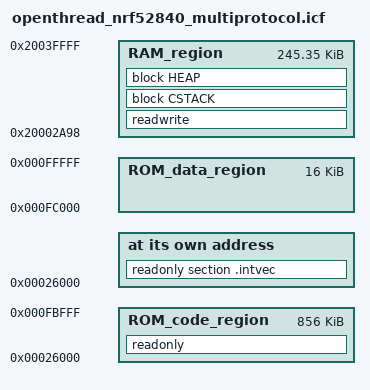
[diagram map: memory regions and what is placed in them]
/*###ICF### Section handled by ICF editor, don't touch! ****/
/*-Editor annotation file-*/
/* IcfEditorFile="$TOOLKIT_DIR$\config\ide\IcfEditor\cortex_v1_0.xml" */
/*-Specials-*/
define symbol __ICFEDIT_intvec_start__ = 0x26000;
/*-Memory Regions-*/
define symbol __ICFEDIT_region_ROM_start__   = 0x26000;
define symbol __ICFEDIT_region_ROM_end__     = 0xfffff;
define symbol __ICFEDIT_region_RAM_start__   = 0x20002a98;
define symbol __ICFEDIT_region_RAM_end__     = 0x2003ffff;
export symbol __ICFEDIT_region_RAM_start__;
export symbol __ICFEDIT_region_RAM_end__;
/*-Sizes-*/
define symbol __ICFEDIT_size_cstack__   = 0x2000;
define symbol __ICFEDIT_size_heap__     = 0x200;
/**** End of ICF editor section. ###ICF###*/

/* Define a region for ROM data area. */
define symbol __ROM_OT_data_size = 4 * 4096;
define symbol __region_ROM_OT_data_start = __ICFEDIT_region_ROM_end__ - __ROM_OT_data_size + 1;
/* Define symbols for flash data driver. */
define symbol __start_ot_flash_data = __region_ROM_OT_data_start;
define symbol __stop_ot_flash_data   = __ICFEDIT_region_ROM_end__ + 1;
export symbol __start_ot_flash_data;
export symbol __stop_ot_flash_data;

define memory mem with size = 4G;
define region ROM_code_region = mem:[from __ICFEDIT_region_ROM_start__ to __region_ROM_OT_data_start - 1];
define region ROM_data_region = mem:[from __region_ROM_OT_data_start   to __ICFEDIT_region_ROM_end__];
define region RAM_region      = mem:[from __ICFEDIT_region_RAM_start__ to __ICFEDIT_region_RAM_end__];

define block CSTACK       with alignment = 8, size = __ICFEDIT_size_cstack__   { };
define block HEAP         with alignment = 8, size = __ICFEDIT_size_heap__     { };

initialize by copy { readwrite };
do not initialize  { section .noinit };

keep { section .intvec };
place at address mem:__ICFEDIT_intvec_start__ { readonly section .intvec };
place in ROM_code_region   { readonly };
place in RAM_region        { readwrite,
                             block CSTACK,
                             block HEAP };

